AUTOSAR XML (schema 4.0)
package /ADAS_Components
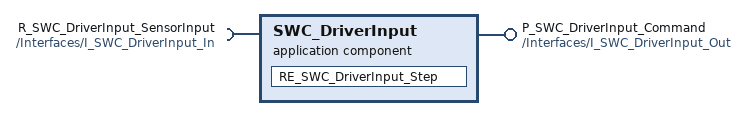
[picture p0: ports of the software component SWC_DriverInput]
  application sw component type SWC_DriverInput  # AUTOSAR Application SWC SWC_DriverInput for ADAS control
    provide port P_SWC_DriverInput_Command: provided-interface=/Interfaces/I_SWC_DriverInput_Out
    require port R_SWC_DriverInput_SensorInput: required-interface=/Interfaces/I_SWC_DriverInput_In
    behavior SWC_DriverInput_Behavior
      runnable RE_SWC_DriverInput_Step: symbol=SWC_DriverInput_Step
